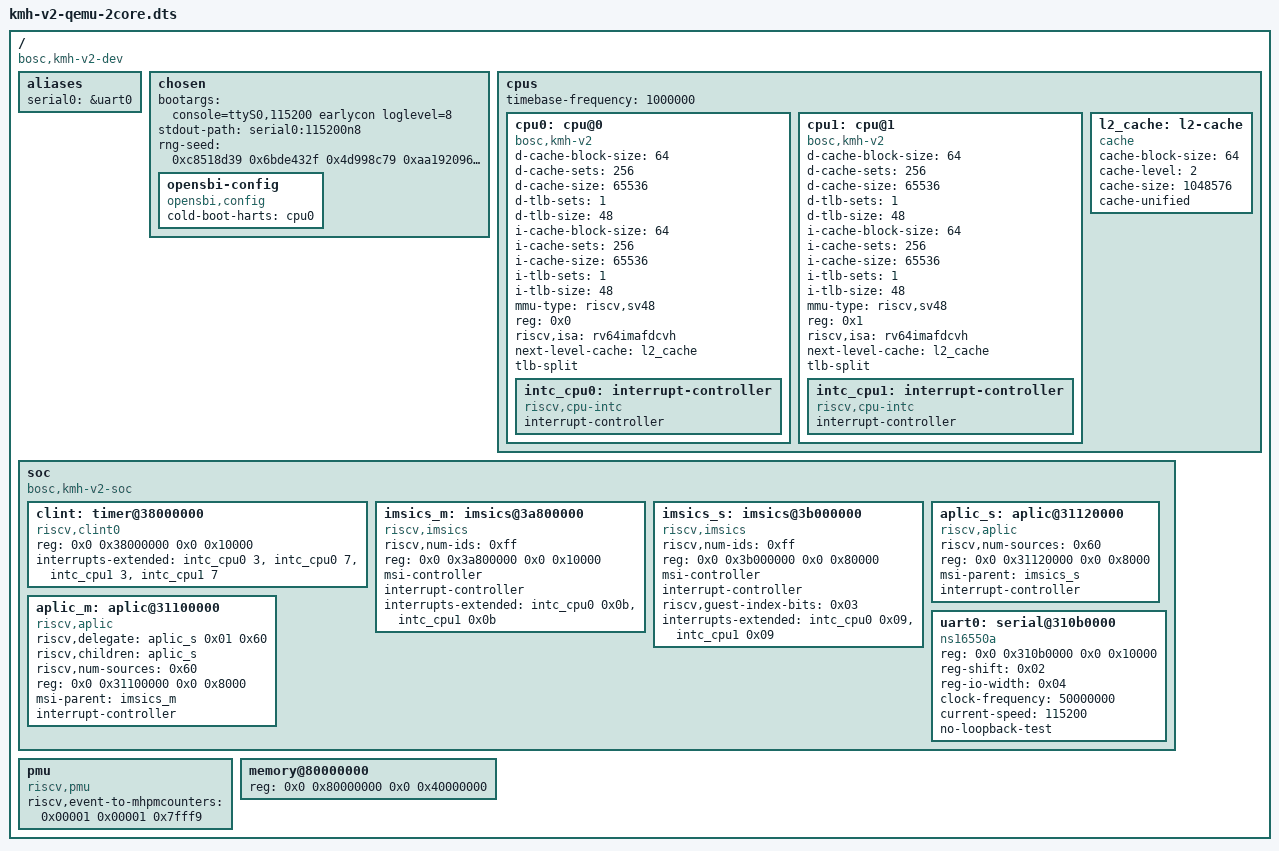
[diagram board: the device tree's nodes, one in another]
// SPDX-License-Identifier: (GPL-2.0 OR MIT)
/* DTS for Xiangshan Kunminghu on QEMU - 2 cores, 1GB RAM */

/dts-v1/;

#include <dt-bindings/interrupt-controller/irq.h>

/ {
	compatible = "bosc,kmh-v2-dev";
	#address-cells = <2>;
	#size-cells = <2>;

	aliases {
		serial0 = &uart0;
	};

	chosen {
		bootargs = "console=ttyS0,115200 earlycon loglevel=8";
		stdout-path = "serial0:115200n8";
		rng-seed = <0xc8518d39 0x6bde432f 0x4d998c79 0xaa192096 0xdbcf36f3 0x532f3ab3 0x965240fe 0xac379c0e>;
		opensbi-config {
			compatible = "opensbi,config";
			cold-boot-harts = <&cpu0>;
		};
	};

	cpus {
		#address-cells = <1>;
		#size-cells = <0>;
		timebase-frequency = <1000000>;

		cpu0: cpu@0 {
			compatible = "bosc,kmh-v2", "riscv";
			d-cache-block-size = <64>;
			d-cache-sets = <256>;
			d-cache-size = <65536>;
			d-tlb-sets = <1>;
			d-tlb-size = <48>;
			device_type = "cpu";
			i-cache-block-size = <64>;
			i-cache-sets = <256>;
			i-cache-size = <65536>;
			i-tlb-sets = <1>;
			i-tlb-size = <48>;
			mmu-type = "riscv,sv48";
			reg = <0x0>;
			riscv,isa = "rv64imafdcvh";
			status = "okay";

			next-level-cache = <&l2_cache>;
			tlb-split;
			intc_cpu0: interrupt-controller {
				#interrupt-cells = <1>;
				compatible = "riscv,cpu-intc";
				interrupt-controller;
			};
		};

		cpu1: cpu@1 {
			compatible = "bosc,kmh-v2", "riscv";
			d-cache-block-size = <64>;
			d-cache-sets = <256>;
			d-cache-size = <65536>;
			d-tlb-sets = <1>;
			d-tlb-size = <48>;
			device_type = "cpu";
			i-cache-block-size = <64>;
			i-cache-sets = <256>;
			i-cache-size = <65536>;
			i-tlb-sets = <1>;
			i-tlb-size = <48>;
			mmu-type = "riscv,sv48";
			reg = <0x1>;
			riscv,isa = "rv64imafdcvh";
			status = "okay";

			next-level-cache = <&l2_cache>;
			tlb-split;
			intc_cpu1: interrupt-controller {
				#interrupt-cells = <1>;
				compatible = "riscv,cpu-intc";
				interrupt-controller;
			};
		};

		l2_cache: l2-cache {
			compatible = "cache";
			cache-block-size = <64>;
			cache-level = <2>;
			cache-size = <1048576>;
			cache-unified;
		};
	};

	soc {
		#address-cells = <2>;
		#size-cells = <2>;
		compatible = "bosc,kmh-v2-soc", "simple-bus";
		ranges;

		clint: timer@38000000 {
			compatible = "riscv,clint0";
			reg = <0x0 0x38000000 0x0 0x10000>;
			interrupts-extended = <&intc_cpu0 3>, <&intc_cpu0 7>,
					      <&intc_cpu1 3>, <&intc_cpu1 7>;
		};

		imsics_m: imsics@3a800000 {
			riscv,num-ids = <0xff>;
			reg = <0x0 0x3a800000 0x0 0x10000>;
			msi-controller;
			interrupt-controller;
			#interrupt-cells = <0x00>;
			compatible = "riscv,imsics";
			interrupts-extended = <&intc_cpu0 0x0b>,
					      <&intc_cpu1 0x0b>;
		};

		imsics_s: imsics@3b000000 {
			riscv,num-ids = <0xff>;
			reg = <0x0 0x3b000000 0x0 0x80000>;
			msi-controller;
			interrupt-controller;
			#interrupt-cells = <0x00>;
			compatible = "riscv,imsics";
			riscv,guest-index-bits = <0x03>;
			interrupts-extended = <&intc_cpu0 0x09>,
					      <&intc_cpu1 0x09>;
		};

		aplic_s: aplic@31120000 {
			riscv,num-sources = <0x60>;
			reg = <0x0 0x31120000 0x0 0x8000>;
			msi-parent = <&imsics_s>;
			interrupt-controller;
			#interrupt-cells = <0x02>;
			compatible = "riscv,aplic";
		};

		aplic_m: aplic@31100000 {
			riscv,delegate = <&aplic_s 0x01 0x60>;
			riscv,children = <&aplic_s>;
			riscv,num-sources = <0x60>;
			reg = <0x0 0x31100000 0x0 0x8000>;
			msi-parent = <&imsics_m>;
			interrupt-controller;
			#interrupt-cells = <0x02>;
			compatible = "riscv,aplic";
		};

		uart0: serial@310b0000 {
			compatible = "ns16550a";
			reg = <0x0 0x310b0000 0x0 0x10000>;
			reg-shift = <0x02>;
			reg-io-width = <0x04>;
			clock-frequency = <50000000>;
			current-speed = <115200>;
			no-loopback-test;
			status = "okay";
		};
	};

	pmu {
		compatible = "riscv,pmu";
		riscv,event-to-mhpmcounters =
			<0x00001 0x00001 0x7fff9>;
	};

	memory@80000000 {
		device_type = "memory";
		reg = <0x0 0x80000000 0x0 0x40000000>; /* 1GB */
	};
};
